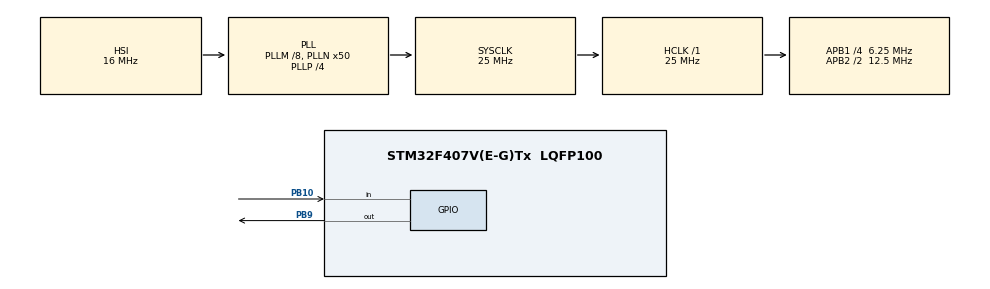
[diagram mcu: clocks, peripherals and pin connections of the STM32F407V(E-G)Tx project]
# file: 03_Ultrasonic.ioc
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Mcu.Family=STM32F4
Mcu.Name=STM32F407V(E-G)Tx
Mcu.Package=LQFP100
NVIC.PriorityGroup=NVIC_PRIORITYGROUP_0
PB10.Signal=GPIO_Input
PB9.Signal=GPIO_Output
PH0-OSC_IN.Mode=HSE-External-Oscillator
PH0-OSC_IN.Signal=RCC_OSC_IN
PH1-OSC_OUT.Mode=HSE-External-Oscillator
PH1-OSC_OUT.Signal=RCC_OSC_OUT
ProjectManager.HeapSize=0x200
ProjectManager.StackSize=0x400
ProjectManager.TargetToolchain=STM32CubeIDE
RCC.48MHZClocksFreq_Value=14285714.285714285
RCC.AHBFreq_Value=25000000
RCC.APB1CLKDivider=RCC_HCLK_DIV4
RCC.APB1Freq_Value=6250000
RCC.APB1TimFreq_Value=12500000
RCC.APB2CLKDivider=RCC_HCLK_DIV2
RCC.APB2Freq_Value=12500000
RCC.APB2TimFreq_Value=25000000
RCC.CortexFreq_Value=25000000
RCC.HCLKFreq_Value=25000000
RCC.HSE_VALUE=8000000
RCC.HSI_VALUE=16000000
RCC.LSE_VALUE=32768
RCC.PLLM=8
RCC.PLLN=50
RCC.PLLP=RCC_PLLP_DIV4
RCC.PLLQ=7
RCC.SYSCLKFreq_VALUE=25000000
RCC.SYSCLKSource=RCC_SYSCLKSOURCE_PLLCLK
RCC.VCOOutputFreq_Value=100000000
VP_TIM3_VS_ClockSourceINT.Mode=Internal
board=STM32F407G-DISC1

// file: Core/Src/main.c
/* USER CODE BEGIN Header */
/**
  ******************************************************************************
  * @file           : main.c
  * @brief          : Main program body
  ******************************************************************************
  * @attention
  *
  * Copyright (c) 2026 STMicroelectronics.
  * All rights reserved.
  *
  * This software is licensed under terms that can be found in the LICENSE file
  * in the root directory of this software component.
  * If no LICENSE file comes with this software, it is provided AS-IS.
  *
  ******************************************************************************
  */
/* USER CODE END Header */
#include "main.h"
#include "stdint.h"

TIM_HandleTypeDef htim3;

void SystemClock_Config(void);
static void MX_GPIO_Init(void);
static void MX_TIM3_Init(void);
/* USER CODE BEGIN PFP */
void delay_us(uint16_t us);
int get_distance(void);

/* USER CODE END PFP */

/* USER CODE BEGIN 0 */
float distance=0;

/* USER CODE END 0 */

int main(void)
{
  /* MCU Configuration--------------------------------------------------------*/
  /* Reset of all peripherals, Initializes the Flash interface and the Systick. */
  HAL_Init();
  /* Configure the sysem clock */
  SystemClock_Config();
  /* Initialize all configured peripherals */
  MX_GPIO_Init();
  MX_TIM3_Init();
  /* USER CODE BEGIN 2 */
  HAL_TIM_Base_Start(&htim3);
  /* USER CODE END 2 */
  /* Infinite loop */
  while (1)
  {
    /* USER CODE BEGIN 3 */
	  distance = get_distance();
	  HAL_Delay(100);
  }
  /* USER CODE END 3 */
}

void SystemClock_Config(void)
{
  RCC_OscInitTypeDef RCC_OscInitStruct = {0};
  RCC_ClkInitTypeDef RCC_ClkInitStruct = {0};

  /** Configure the main internal regulator output voltage
  */
  __HAL_RCC_PWR_CLK_ENABLE();
  __HAL_PWR_VOLTAGESCALING_CONFIG(PWR_REGULATOR_VOLTAGE_SCALE1);

  /** Initializes the RCC Oscillators according to the specified parameters
  * in the RCC_OscInitTypeDef structure.
  */
  RCC_OscInitStruct.OscillatorType = RCC_OSCILLATORTYPE_HSI;
  RCC_OscInitStruct.HSIState = RCC_HSI_ON;
  RCC_OscInitStruct.HSICalibrationValue = RCC_HSICALIBRATION_DEFAULT;
  RCC_OscInitStruct.PLL.PLLState = RCC_PLL_ON;
  RCC_OscInitStruct.PLL.PLLSource = RCC_PLLSOURCE_HSI;
  RCC_OscInitStruct.PLL.PLLM = 8;
  RCC_OscInitStruct.PLL.PLLN = 50;
  RCC_OscInitStruct.PLL.PLLP = RCC_PLLP_DIV4;
  RCC_OscInitStruct.PLL.PLLQ = 7;
  if (HAL_RCC_OscConfig(&RCC_OscInitStruct) != HAL_OK)
  {
    Error_Handler();
  }

  /** Initializes the CPU, AHB and APB buses clocks
  */
  RCC_ClkInitStruct.ClockType = RCC_CLOCKTYPE_HCLK|RCC_CLOCKTYPE_SYSCLK
                              |RCC_CLOCKTYPE_PCLK1|RCC_CLOCKTYPE_PCLK2;
  RCC_ClkInitStruct.SYSCLKSource = RCC_SYSCLKSOURCE_PLLCLK;
  RCC_ClkInitStruct.AHBCLKDivider = RCC_SYSCLK_DIV1;
  RCC_ClkInitStruct.APB1CLKDivider = RCC_HCLK_DIV4;
  RCC_ClkInitStruct.APB2CLKDivider = RCC_HCLK_DIV2;

  if (HAL_RCC_ClockConfig(&RCC_ClkInitStruct, FLASH_LATENCY_0) != HAL_OK)
  {
    Error_Handler();
  }
}

static void MX_TIM3_Init(void)
{

  TIM_ClockConfigTypeDef sClockSourceConfig = {0};
  TIM_MasterConfigTypeDef sMasterConfig = {0};

  htim3.Instance = TIM3;
  htim3.Init.Prescaler = 15;
  htim3.Init.CounterMode = TIM_COUNTERMODE_UP;
  htim3.Init.Period = 65535;
  htim3.Init.ClockDivision = TIM_CLOCKDIVISION_DIV1;
  htim3.Init.AutoReloadPreload = TIM_AUTORELOAD_PRELOAD_DISABLE;
  if (HAL_TIM_Base_Init(&htim3) != HAL_OK)
  {
    Error_Handler();
  }
  sClockSourceConfig.ClockSource = TIM_CLOCKSOURCE_INTERNAL;
  if (HAL_TIM_ConfigClockSource(&htim3, &sClockSourceConfig) != HAL_OK)
  {
    Error_Handler();
  }
  sMasterConfig.MasterOutputTrigger = TIM_TRGO_RESET;
  sMasterConfig.MasterSlaveMode = TIM_MASTERSLAVEMODE_DISABLE;
  if (HAL_TIMEx_MasterConfigSynchronization(&htim3, &sMasterConfig) != HAL_OK)
  {
    Error_Handler();
  }

}

static void MX_GPIO_Init(void)
{
  GPIO_InitTypeDef GPIO_InitStruct = {0};

  /* GPIO Ports Clock Enable */
  __HAL_RCC_GPIOH_CLK_ENABLE();
  __HAL_RCC_GPIOB_CLK_ENABLE();

  /*Configure GPIO pin Output Level */
  HAL_GPIO_WritePin(GPIOB, GPIO_PIN_9, GPIO_PIN_RESET);

  /*Configure GPIO pin : PB10 */
  GPIO_InitStruct.Pin = GPIO_PIN_10;
  GPIO_InitStruct.Mode = GPIO_MODE_INPUT;
  GPIO_InitStruct.Pull = GPIO_NOPULL;
  HAL_GPIO_Init(GPIOB, &GPIO_InitStruct);

  /*Configure GPIO pin : PB9 */
  GPIO_InitStruct.Pin = GPIO_PIN_9;
  GPIO_InitStruct.Mode = GPIO_MODE_OUTPUT_PP;
  GPIO_InitStruct.Pull = GPIO_NOPULL;
  GPIO_InitStruct.Speed = GPIO_SPEED_FREQ_LOW;
  HAL_GPIO_Init(GPIOB, &GPIO_InitStruct);

}

/* USER CODE BEGIN 4 */

void delay_us(uint16_t us)
{
    __HAL_TIM_SET_COUNTER(&htim3, 0);

    while(__HAL_TIM_GET_COUNTER(&htim3) < us);
}

int get_distance(void)
{
    uint32_t duration;
    uint32_t timeout;

    // Trigger LOW
    HAL_GPIO_WritePin(GPIOB, GPIO_PIN_9, GPIO_PIN_RESET);
    delay_us(2);

    // Trigger HIGH for 10us
    HAL_GPIO_WritePin(GPIOB, GPIO_PIN_9, GPIO_PIN_SET);
    delay_us(10);

    // Trigger LOW
    HAL_GPIO_WritePin(GPIOB, GPIO_PIN_9, GPIO_PIN_RESET);

    // Wait for ECHO HIGH
    timeout = 30000;

    while(HAL_GPIO_ReadPin(GPIOB, GPIO_PIN_10) == GPIO_PIN_RESET)
    {
        if(--timeout == 0)
        {
            return -1;
        }
    }

    // Start timer
    __HAL_TIM_SET_COUNTER(&htim3, 0);

    // Wait for ECHO LOW
    while(HAL_GPIO_ReadPin(GPIOB, GPIO_PIN_10) == GPIO_PIN_SET)
    {
        if(__HAL_TIM_GET_COUNTER(&htim3) > 30000)
        {
            break;
        }
    }

    // Read timer value
    duration = __HAL_TIM_GET_COUNTER(&htim3);

    // Convert to distance in cm
    return duration / 58;
}
/* USER CODE END 4 */

void Error_Handler(void)
{
  __disable_irq();
  while (1)
  {
  }
}
